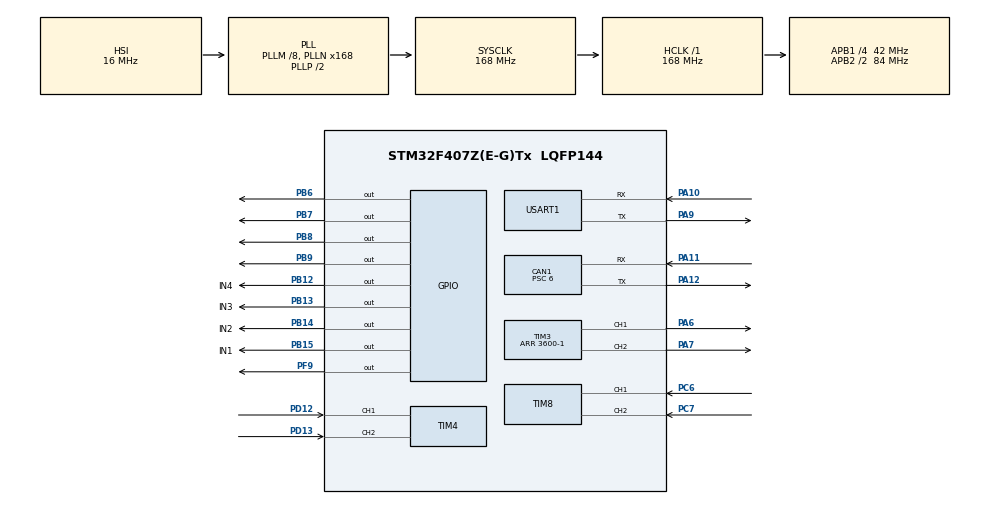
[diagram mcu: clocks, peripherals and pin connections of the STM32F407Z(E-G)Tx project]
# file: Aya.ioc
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CAN1.BS1=CAN_BS1_3TQ
CAN1.BS2=CAN_BS2_3TQ
CAN1.CalculateBaudRate=1000000
CAN1.CalculateTimeBit=1000
CAN1.CalculateTimeQuantum=142.85714285714286
CAN1.Prescaler=6
Mcu.Family=STM32F4
Mcu.Name=STM32F407Z(E-G)Tx
Mcu.Package=LQFP144
NVIC.PriorityGroup=NVIC_PRIORITYGROUP_4
NVIC.TIM7_IRQn=true\:15\:0\:false\:false\:true\:false\:true\:true
NVIC.TimeBase=TIM7_IRQn
NVIC.TimeBaseIP=TIM7
NVIC.USART1_IRQn=true\:0\:0\:false\:false\:true\:true\:true\:true
PA10.Mode=Asynchronous
PA10.Signal=USART1_RX
PA11.Mode=CAN_Activate
PA11.Signal=CAN1_RX
PA12.Mode=CAN_Activate
PA12.Signal=CAN1_TX
PA13.Mode=Serial_Wire
PA13.Signal=SYS_JTMS-SWDIO
PA14.Mode=Serial_Wire
PA14.Signal=SYS_JTCK-SWCLK
PA6.Signal=S_TIM3_CH1
PA7.Signal=S_TIM3_CH2
PA9.Mode=Asynchronous
PA9.Signal=USART1_TX
PB12.GPIO_Label=IN4
PB12.GPIO_PuPd=GPIO_PULLDOWN
PB12.GPIO_Speed=GPIO_SPEED_FREQ_HIGH
PB12.PinState=GPIO_PIN_SET
PB12.Signal=GPIO_Output
PB13.GPIO_Label=IN3
PB13.GPIO_Speed=GPIO_SPEED_FREQ_HIGH
PB13.PinState=GPIO_PIN_SET
PB13.Signal=GPIO_Output
PB14.GPIO_Label=IN2
PB14.GPIO_PuPd=GPIO_PULLDOWN
PB14.GPIO_Speed=GPIO_SPEED_FREQ_HIGH
PB14.PinState=GPIO_PIN_SET
PB14.Signal=GPIO_Output
PB15.GPIO_Label=IN1
PB15.GPIO_PuPd=GPIO_PULLDOWN
PB15.GPIO_Speed=GPIO_SPEED_FREQ_HIGH
PB15.PinState=GPIO_PIN_SET
PB15.Signal=GPIO_Output
PB6.Signal=GPIO_Output
PB7.Signal=GPIO_Output
PB8.Signal=GPIO_Output
PB9.Signal=GPIO_Output
PC6.Signal=S_TIM8_CH1
PC7.Signal=S_TIM8_CH2
PD12.Signal=S_TIM4_CH1
PD13.Signal=S_TIM4_CH2
PF9.Signal=GPIO_Output
PH0-OSC_IN.Mode=HSE-External-Oscillator
PH0-OSC_IN.Signal=RCC_OSC_IN
PH1-OSC_OUT.Mode=HSE-External-Oscillator
PH1-OSC_OUT.Signal=RCC_OSC_OUT
ProjectManager.HeapSize=0x200
ProjectManager.StackSize=0x400
ProjectManager.TargetToolchain=MDK-ARM V5.32
RCC.48MHZClocksFreq_Value=84000000
RCC.AHBFreq_Value=168000000
RCC.APB1CLKDivider=RCC_HCLK_DIV4
RCC.APB1Freq_Value=42000000
RCC.APB1TimFreq_Value=84000000
RCC.APB2CLKDivider=RCC_HCLK_DIV2
RCC.APB2Freq_Value=84000000
RCC.APB2TimFreq_Value=168000000
RCC.CortexFreq_Value=168000000
RCC.HCLKFreq_Value=168000000
RCC.HSE_VALUE=25000000
RCC.HSI_VALUE=16000000
RCC.LSE_VALUE=32768
RCC.PLLM=8
RCC.PLLN=168
RCC.SYSCLKFreq_VALUE=168000000
RCC.SYSCLKSource=RCC_SYSCLKSOURCE_PLLCLK
RCC.VCOOutputFreq_Value=336000000
SH.S_TIM3_CH1.0=TIM3_CH1,PWM Generation1 CH1
SH.S_TIM3_CH2.0=TIM3_CH2,PWM Generation2 CH2
SH.S_TIM4_CH1.0=TIM4_CH1,Encoder_Interface
SH.S_TIM4_CH2.0=TIM4_CH2,Encoder_Interface
SH.S_TIM8_CH1.0=TIM8_CH1,Encoder_Interface
SH.S_TIM8_CH2.0=TIM8_CH2,Encoder_Interface
TIM2.Period=1000-1
TIM2.Prescaler=1680-1
TIM3.Channel-PWM\ Generation1\ CH1=TIM_CHANNEL_1
TIM3.Channel-PWM\ Generation2\ CH2=TIM_CHANNEL_2
TIM3.Period=3600-1
TIM4.EncoderMode=TIM_ENCODERMODE_TI12
TIM4.IC1Filter=10
TIM4.IC2Filter=10
USART1.VirtualMode=VM_ASYNC
VP_SYS_VS_tim7.Mode=TIM7
VP_TIM2_VS_ClockSourceINT.Mode=Internal
VP_TIM3_VS_ClockSourceINT.Mode=Internal
board=custom

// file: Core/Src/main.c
/* USER CODE BEGIN Header */
/**
  ******************************************************************************
  * @file           : main.c
  * @brief          : Main program body
  ******************************************************************************
  * @attention
  *
  * Copyright (c) 2024 STMicroelectronics.
  * All rights reserved.
  *
  * This software is licensed under terms that can be found in the LICENSE file
  * in the root directory of this software component.
  * If no LICENSE file comes with this software, it is provided AS-IS.
  *
  ******************************************************************************
  */
/* USER CODE END Header */
#include "main.h"
#include "can.h"
#include "tim.h"
#include "usart.h"
#include "gpio.h"

/* USER CODE BEGIN PTD */
uint8_t cmd;
/* USER CODE END PTD */

void SystemClock_Config(void);

int main(void)
{

  /* MCU Configuration--------------------------------------------------------*/

  /* Reset of all peripherals, Initializes the Flash interface and the Systick. */
  HAL_Init();

  /* Configure the system clock */
  SystemClock_Config();

  /* Initialize all configured peripherals */
  MX_GPIO_Init();
  MX_CAN1_Init();
  MX_TIM2_Init();
  MX_TIM3_Init();
  MX_TIM4_Init();
  MX_TIM8_Init();
  MX_USART1_UART_Init();
  /* USER CODE BEGIN 2 */
    OLED_Init();
	HAL_UART_Receive_IT(&huart1,(void *)&cmd, 1);
	MX_RT_Thread_Init();
  /* USER CODE END 2 */

  /* Infinite loop */
  while (1)
  {

  }
}

void SystemClock_Config(void)
{
  RCC_OscInitTypeDef RCC_OscInitStruct = {0};
  RCC_ClkInitTypeDef RCC_ClkInitStruct = {0};

  /** Configure the main internal regulator output voltage
  */
  __HAL_RCC_PWR_CLK_ENABLE();
  __HAL_PWR_VOLTAGESCALING_CONFIG(PWR_REGULATOR_VOLTAGE_SCALE1);

  /** Initializes the RCC Oscillators according to the specified parameters
  * in the RCC_OscInitTypeDef structure.
  */
  RCC_OscInitStruct.OscillatorType = RCC_OSCILLATORTYPE_HSI;
  RCC_OscInitStruct.HSIState = RCC_HSI_ON;
  RCC_OscInitStruct.HSICalibrationValue = RCC_HSICALIBRATION_DEFAULT;
  RCC_OscInitStruct.PLL.PLLState = RCC_PLL_ON;
  RCC_OscInitStruct.PLL.PLLSource = RCC_PLLSOURCE_HSI;
  RCC_OscInitStruct.PLL.PLLM = 8;
  RCC_OscInitStruct.PLL.PLLN = 168;
  RCC_OscInitStruct.PLL.PLLP = RCC_PLLP_DIV2;
  RCC_OscInitStruct.PLL.PLLQ = 4;
  if (HAL_RCC_OscConfig(&RCC_OscInitStruct) != HAL_OK)
  {
    Error_Handler();
  }

  /** Initializes the CPU, AHB and APB buses clocks
  */
  RCC_ClkInitStruct.ClockType = RCC_CLOCKTYPE_HCLK|RCC_CLOCKTYPE_SYSCLK
                              |RCC_CLOCKTYPE_PCLK1|RCC_CLOCKTYPE_PCLK2;
  RCC_ClkInitStruct.SYSCLKSource = RCC_SYSCLKSOURCE_PLLCLK;
  RCC_ClkInitStruct.AHBCLKDivider = RCC_SYSCLK_DIV1;
  RCC_ClkInitStruct.APB1CLKDivider = RCC_HCLK_DIV4;
  RCC_ClkInitStruct.APB2CLKDivider = RCC_HCLK_DIV2;

  if (HAL_RCC_ClockConfig(&RCC_ClkInitStruct, FLASH_LATENCY_5) != HAL_OK)
  {
    Error_Handler();
  }
}

/* USER CODE BEGIN 4 */
void HAL_UART_RxCpltCallback(UART_HandleTypeDef *huart)
{
	uint16_t Serial_RxData;
  if(huart->Instance==USART1){
		Serial_RxData=cmd;
//		openmv_receive(Serial_RxData);
	}
	HAL_UART_Receive_IT(&huart1,(void *)&cmd, 1);
}
/* USER CODE END 4 */

void HAL_TIM_PeriodElapsedCallback(TIM_HandleTypeDef *htim)
{
  if (htim->Instance == TIM7) {
    HAL_IncTick();
  }
}

void Error_Handler(void)
{
  __disable_irq();
  while (1)
  {
  }
}
